# 3066H register map
File version: 1.0
3066H registers
Registers are 32-bit, access per field, reset 0x0 unless marked. A register's access mark holds for its fields unless they carry their own. Offsets are from the block's base; lines under a group give offsets from that group; [hi:lo] are bit positions; {n}, {i} and the like mark numbered series; 'fields as' and 'values as' point back to an identical list; <NAME> marks a mode.

## Memory map
0x10000000 CRG size 0xF14 — CRG peripheral interface
0x10010000 CMM0 size 0x20 — CMM0 peripheral interface
0x10011000 CMM1 size 0x20
0x10020000 CFD size 0x20 — CFD peripheral interface
0x10100000 SYSCTRL0 size 0x8000 — SYSCTRL0 peripheral interface
0x10100000 SYSCTRL1 size 0x10000 — SYSCTRL1 peripheral interface
0x14000000 UART0 size 0x64 — UART0 peripheral interface
0x14001000 UART1 size 0x64
0x14002000 UART2 size 0x64
0x14003000 UART3 size 0x64
0x14004000 UART4 size 0x64
0x14005000 UART5 size 0x64
0x14006000 UART6 size 0x64
0x14007000 UART7 size 0x64
0x14100000 I2C0 size 0x110 — I2C0 peripheral interface
0x14101000 I2C1 size 0x110
0x14102000 I2C2 size 0x110
0x14200000 SPI0 size 0x34 — SPI0 peripheral interface
0x14201000 SPI1 size 0x34
0x14202000 SPI2 size 0x34
0x14300000 TIMER0 size 0x24 — TIMER0 peripheral interface
0x14301000 TIMER1 size 0x24
0x14302000 TIMER2 size 0x24
0x14303000 TIMER3 size 0x24
0x14304000 TIMER4 size 0x24
0x14305000 TIMER5 size 0x24
0x14400000 WWDG0 size 0x20 — WWDG0 peripheral interface
0x14401000 IWDG size 0x24 — IWDG peripheral interface
0x14402000 WWDG1 size 0x20
0x14403000 WWDG2 size 0x20
{0x14500000+0x1000*n} GPIO{n} size 0x504 (n=1..16)
0x14680000 MCAN0 size 0x818 — MCAN0 peripheral interface
0x14684000 MCAN1 size 0x818
0x14688000 MCAN2 size 0x818
0x14700000 GPT0 size 0x508 — GPT0 peripheral interface
0x14701000 GPT1 size 0x508
0x147E0000 PMC size 0xF10 — PMC peripheral interface
0x147E0000 PMC size 0xF10 — PMC peripheral interface
0x147F0000 IOCMG_AON size 0x200 — IOCMG_AON peripheral interface
0x147F0000 IOCMG_CORE size 0x1000 — IOCMG_CORE peripheral interface
0x14800000 CRC size 0x24 — CRC peripheral interface
0x14820000 IPCM size 0xA04 — IPCM peripheral interface
0x14A00000 APT0 size 0xB10 — APT0 peripheral interface
{0x14A00000+0x1000*n} APT{n} size 0xB10 (n=1..15)
0x14A1F000 APT_XBAR size 0x940 — APT_XBAR peripheral interface
0x14A1FF00 DLL size 0x940 — DLL peripheral interface
0x14A20000 SRM size 0xC08 — SRM peripheral interface
0x14B00000 CAPM0 size 0x50 — CAPM0 peripheral interface
0x14B01000 CAPM1 size 0x50
0x14B02000 CAPM2 size 0x50
0x14B03000 CAPM_COMM size 0x60 — CAPM_COMM peripheral interface
0x14C00000 QDM0 size 0x6C — QDM0 peripheral interface
0x14C01000 QDM1 size 0x6C
0x14C02000 QDM2 size 0x6C
0x14C03000 QDM3 size 0x6C
0x18000000 ADC0 size 0x850 — ADC0 peripheral interface
0x18001000 ADC1 size 0x850
0x18002000 ADC2 size 0x850
0x18003000 ADC3 size 0x850
0x18200000 PGA0 size 0x20 — PGA0 peripheral interface
0x18201000 PGA1 size 0x20
0x18202000 PGA2 size 0x20
0x18203000 PGA3 size 0x20
0x18300000 ACMP0 size 0xA0 — ACMP peripheral interface
0x18301000 ACMP1 size 0xA0
0x18302000 ACMP2 size 0xA0
0x18303000 ACMP3 size 0xA0
0x18304000 ACMP4 size 0xA0
0x18305000 ACMP5 size 0xA0
0x18306000 ACMP6 size 0xA0
0x18307000 ACMP7 size 0xA0
0x18400000 DAC0 size 0xA0 — DAC0 peripheral interface
0x18400000 DAC — DAC peripheral interface
0x18401000 DAC1 size 0xA0
0x18402000 DAC2 size 0xA0
0x18403000 DAC3 size 0xA0
0x18404000 DAC4 size 0xA0
0x18405000 DAC5 size 0xA0
0x18406000 DAC6 size 0xA0
0x18407000 DAC7 size 0xA0
0x18408000 DACBUFF size 0xA0
0x18500000 TSENSOR size 0x20 — TSENSOR peripheral interface
0x1C000000 DMA0 size 0x114 — DMA0 peripheral interface
0x1C000000 GPIO0 size 0x504 — GPIO0 peripheral interface
0x1C001000 DMA1 size 0x114
0x1C0E0000 FMC size 0xB0 — FMC peripheral interface

## PMC — PMC peripheral interface
Base 0x147E0000
Same registers: PMC 0x147E0000, PMC 0x147E0000
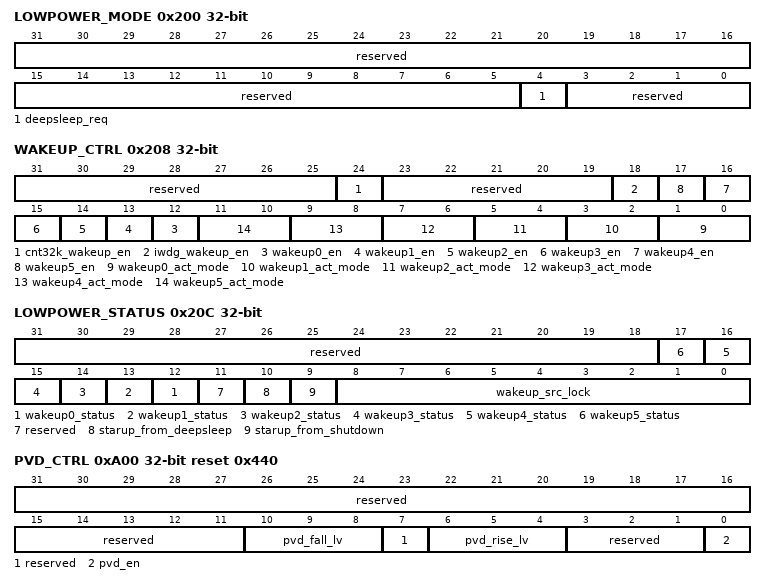
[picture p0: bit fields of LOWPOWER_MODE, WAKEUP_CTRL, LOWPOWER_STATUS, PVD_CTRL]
0x200 LOWPOWER_MODE — LOWPOWER_MODE为低功耗模式控制寄存器。
  [31:5] reserved ro — 保留。
  [4] deepsleep_req wo — 系统进入deepsleep模式请求。 对此寄存器位域写1操作将触发MCU进入deepsleep模式流程。
  [3:0] reserved ro — 保留。
0x204 CNT32K_WAKE_CYC rw reset 0xFFFF — CNT32K_WAKE_CYC为定时唤醒周期设置寄存器。
  [31:0] cnt32k_wakeup_cycle — 定时唤醒周期数（计数时钟clk_losc）。
0x208 WAKEUP_CTRL — WAKEUP_CTRL为deepsleep模式唤醒控制寄存器。
  [31:25] reserved ro — 保留。
  [24] cnt32k_wakeup_en rw — 定时唤醒使能。 0：不使能； 1：使能。
  [23:19] reserved ro — 保留。
  [18] iwdg_wakeup_en rw — IWDG唤醒使能。 0：不使能； 1：使能。
  [n+12] wakeup{n}_en rw (n=0..5) — WAKEUP{n}使能。 0：不使能； 1：使能。
  [2n+1:2n] wakeup{n}_act_mode rw (n=0..5) — WAKEUP{n}有效模式选择。 00：上升沿有效； 01：下降沿有效； 10：高电平有效； 11：低电平有效。
0x20C LOWPOWER_STATUS ro — LOWPOWER_STATUS为低功耗状态查询寄存器。
  [31:18] reserved — 保留。
  [n+12] wakeup{n}_status (n=0..5) — WAKEUP{n}唤醒源状态。 0：唤醒源低电平； 1：唤醒源高电平。
  [11] reserved — 保留。
  [10] starup_from_deepsleep — 从deepsleep状态启动标识。 0：未从deepsleep模式启动； 1：从deepsleep模式启动。
  [9] starup_from_shutdown — MCU初次上电启动标识。 0：不是初次上电启动； 1：是初次上电启动。
  [8:0] wakeup_src_lock — 启动唤醒源查询。 bit[8]：IWDG唤醒； bit[7]：RESETN管脚唤醒； bit[6]：WAKEUP5唤醒； bit[5]：WAKEUP4唤醒； bit[4]：WAKEUP3唤醒； bit[3]：WAKEUP2唤醒； bit[2]：WAKEUP1唤醒； bit[1]：WAKEUP0唤醒； bit[0]：cnt32k定时唤醒。
0xA00 PVD_CTRL reset 0x440 — PVD_CTRL为PVD控制寄存器。
  [31:11] reserved ro — 保留。
  [10:8] pvd_fall_lv rw — PVD下降沿阈值。 000：2.08V； 001：2.18V； 010：2.28V； 011：2.38V； 100：2.48V； 101：2.58V； 110：2.68V； 111：2.78V。
  [7] reserved ro — 保留。
  [6:4] pvd_rise_lv rw — PVD上升沿阈值。 000：2.18V； 001：2.28V； 010：2.38V； 011：2.48V； 100：2.58V； 101：2.68V； 110：2.78V； 111：2.88V。
  [3:1] reserved ro — 保留。
  [0] pvd_en rw — PVD使能。 0：不使能； 1：使能。
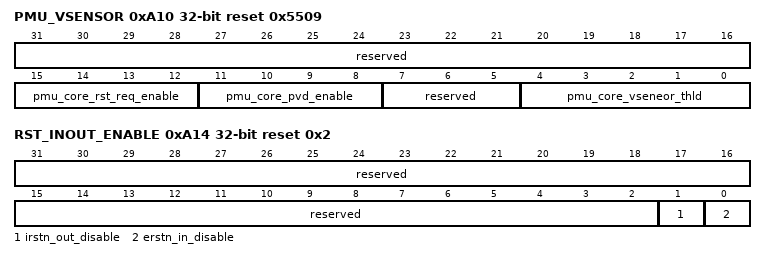
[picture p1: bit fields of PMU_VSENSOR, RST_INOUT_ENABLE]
0xA10 PMU_VSENSOR reset 0x5509 — PMU_VSENSOR为CORE域电压监控寄存器。
  [31:16] reserved ro — 保留。
  [15:12] pmu_core_rst_req_enable rw — CORE PVD输出的rst_req是否有效使能，多数判决，0x0时关闭此功能，其他值开启。 默认不使能。
  [11:8] pmu_core_pvd_enable rw — PMU CORE域电压监控使能，多数判决，0x0时关闭此功能，其他值开启。 默认不使能。
  [7:5] reserved ro — 保留。
  [4:0] pmu_core_vseneor_thld rw — bit[4:0] PMU CORE域电压监控阈值配置，默认0.896V，配置值为0x9，step为16mV。
0xA14 RST_INOUT_ENABLE reset 0x2 — RST_INOUT_ENABLE为RST信号输入输出控制使能寄存器。
  [31:2] reserved ro — 保留。
  [1] irstn_out_disable rw — 内部复位输出控制控制信号。 0：内部复位输出使能； 1：内部复位输出禁止。
  [0] erstn_in_disable rw — 外部复位输入控制控制信号。 0：外部复位输入使能； 1：外部复位输入禁止。
{0xF00+4i} AON_USER_REG{i} rw (i=0..3) — AON_USER_REG{i}为AON域用户寄存器{i}。
  [31:0] aon_user_reg{i} — AON电源域通用寄存器{i}。
